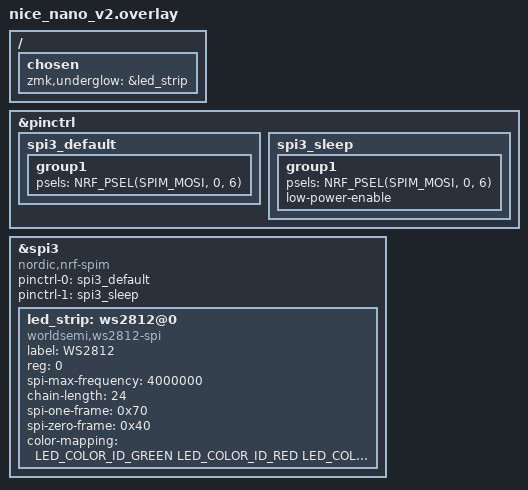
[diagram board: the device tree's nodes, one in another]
/*
 * Copyright (c) 2020 ZMK Contributors
 *
 * SPDX-License-Identifier: MIT
 */

#include <dt-bindings/led/led.h>

/*
 * RGB Underglow Configuration for nice!nano v2
 * LED Count: 24 per half (48 total)
 * Pin: P0.06 (SPI3 MOSI)
 */

&pinctrl {
    spi3_default: spi3_default {
        group1 {
            psels = <NRF_PSEL(SPIM_MOSI, 0, 6)>;
        };
    };

    spi3_sleep: spi3_sleep {
        group1 {
            psels = <NRF_PSEL(SPIM_MOSI, 0, 6)>;
            low-power-enable;
        };
    };
};

&spi3 {
    compatible = "nordic,nrf-spim";
    status = "okay";

    pinctrl-0 = <&spi3_default>;
    pinctrl-1 = <&spi3_sleep>;
    pinctrl-names = "default", "sleep";

    led_strip: ws2812@0 {
        compatible = "worldsemi,ws2812-spi";
        label = "WS2812";

        reg = <0>;
        spi-max-frequency = <4000000>;

        /* 各ハーフ24個のLED（片側はパーツ未実装でもOK） */
        chain-length = <24>;
        spi-one-frame = <0x70>;
        spi-zero-frame = <0x40>;

        color-mapping = <LED_COLOR_ID_GREEN
                         LED_COLOR_ID_RED
                         LED_COLOR_ID_BLUE>;
    };
};

/ {
    chosen {
        zmk,underglow = &led_strip;
    };
};
